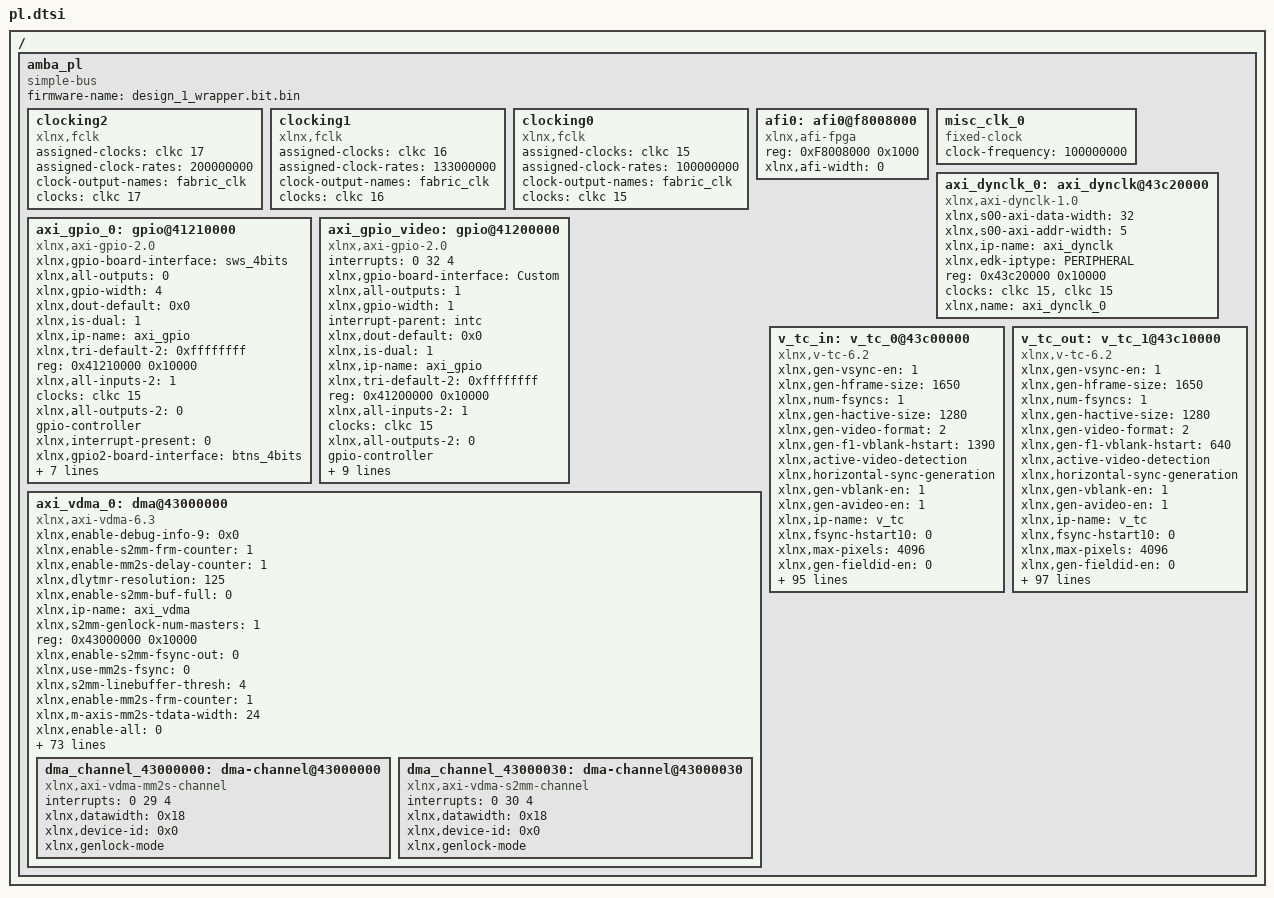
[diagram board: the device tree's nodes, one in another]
/ {
	amba_pl: amba_pl {
		ranges;
		compatible = "simple-bus";
		#address-cells = <1>;
		#size-cells = <1>;
		firmware-name = "design_1_wrapper.bit.bin";
		clocking2: clocking2 {
			compatible = "xlnx,fclk";
			assigned-clocks = <&clkc 17>;
			assigned-clock-rates = <200000000>;
			#clock-cells = <0>;
			clock-output-names = "fabric_clk";
			clocks = <&clkc 17>;
		};
		clocking1: clocking1 {
			compatible = "xlnx,fclk";
			assigned-clocks = <&clkc 16>;
			assigned-clock-rates = <133000000>;
			#clock-cells = <0>;
			clock-output-names = "fabric_clk";
			clocks = <&clkc 16>;
		};
		clocking0: clocking0 {
			compatible = "xlnx,fclk";
			assigned-clocks = <&clkc 15>;
			assigned-clock-rates = <100000000>;
			#clock-cells = <0>;
			clock-output-names = "fabric_clk";
			clocks = <&clkc 15>;
		};
		afi0: afi0@f8008000 {
			status = "okay";
			compatible = "xlnx,afi-fpga";
			#address-cells = <1>;
			reg = <0xF8008000 0x1000>;
			#size-cells = <0>;
			xlnx,afi-width = <0>;
		};
		misc_clk_0: misc_clk_0 {
			compatible = "fixed-clock";
			clock-frequency = <100000000>;
			#clock-cells = <0>;
		};
		axi_dynclk_0: axi_dynclk@43c20000 {
			xlnx,s00-axi-data-width = <32>;
			compatible = "xlnx,axi-dynclk-1.0";
			status = "okay";
			clock-names = "REF_CLK_I" , "s00_axi_aclk";
			xlnx,s00-axi-addr-width = <5>;
			xlnx,ip-name = "axi_dynclk";
			xlnx,edk-iptype = "PERIPHERAL";
			reg = <0x43c20000 0x10000>;
			clocks = <&clkc 15>, <&clkc 15>;
			xlnx,name = "axi_dynclk_0";
		};
		axi_gpio_0: gpio@41210000 {
			xlnx,gpio-board-interface = "sws_4bits";
			compatible = "xlnx,axi-gpio-2.0" , "xlnx,xps-gpio-1.00.a";
			xlnx,all-outputs = <0>;
			#gpio-cells = <2>;
			xlnx,gpio-width = <4>;
			xlnx,dout-default = <0x0>;
			xlnx,is-dual = <1>;
			xlnx,ip-name = "axi_gpio";
			xlnx,tri-default-2 = <0xffffffff>;
			reg = <0x41210000 0x10000>;
			xlnx,all-inputs-2 = <1>;
			clocks = <&clkc 15>;
			xlnx,all-outputs-2 = <0>;
			gpio-controller;
			xlnx,interrupt-present = <0>;
			xlnx,gpio2-board-interface = "btns_4bits";
			xlnx,edk-iptype = "PERIPHERAL";
			xlnx,dout-default-2 = <0x0>;
			status = "okay";
			xlnx,gpio2-width = <4>;
			clock-names = "s_axi_aclk";
			xlnx,use-board-flow;
			xlnx,tri-default = <0xffffffff>;
			xlnx,name = "axi_gpio_0";
			xlnx,all-inputs = <1>;
		};
		axi_gpio_video: gpio@41200000 {
			#interrupt-cells = <2>;
			interrupts = < 0 32 4 >;
			xlnx,gpio-board-interface = "Custom";
			compatible = "xlnx,axi-gpio-2.0" , "xlnx,xps-gpio-1.00.a";
			xlnx,all-outputs = <1>;
			#gpio-cells = <2>;
			xlnx,gpio-width = <1>;
			interrupt-parent = <&intc>;
			xlnx,dout-default = <0x0>;
			xlnx,is-dual = <1>;
			xlnx,ip-name = "axi_gpio";
			xlnx,tri-default-2 = <0xffffffff>;
			reg = <0x41200000 0x10000>;
			xlnx,all-inputs-2 = <1>;
			clocks = <&clkc 15>;
			xlnx,all-outputs-2 = <0>;
			gpio-controller;
			xlnx,interrupt-present = <1>;
			xlnx,gpio2-board-interface = "Custom";
			xlnx,edk-iptype = "PERIPHERAL";
			xlnx,dout-default-2 = <0x0>;
			status = "okay";
			xlnx,gpio2-width = <1>;
			clock-names = "s_axi_aclk";
			interrupt-controller;
			interrupt-names = "ip2intc_irpt";
			xlnx,tri-default = <0xffffffff>;
			xlnx,name = "axi_gpio_video";
			xlnx,all-inputs = <0>;
		};
		axi_vdma_0: dma@43000000 {
			xlnx,enable-debug-info-9 = <0x0>;
			xlnx,enable-s2mm-frm-counter = <1>;
			xlnx,enable-mm2s-delay-counter = <1>;
			xlnx,dlytmr-resolution = <125>;
			xlnx,enable-s2mm-buf-full = <0>;
			xlnx,ip-name = "axi_vdma";
			xlnx,s2mm-genlock-num-masters = <1>;
			reg = <0x43000000 0x10000>;
			xlnx,enable-s2mm-fsync-out = <0>;
			xlnx,use-mm2s-fsync = <0>;
			xlnx,s2mm-linebuffer-thresh = <4>;
			xlnx,enable-mm2s-frm-counter = <1>;
			xlnx,m-axis-mm2s-tdata-width = <24>;
			xlnx,enable-all = <0>;
			xlnx,dynamic-resolution = <1>;
			xlnx,enable-s2mm-rst-out = <0>;
			interrupt-names = "mm2s_introut" , "s2mm_introut";
			xlnx,s2mm-sof-enable = <0x1>;
			xlnx,mm2s-genlock-num-masters = <1>;
			xlnx,enable-mm2s-fsync-out = <0>;
			xlnx,mm2s-linebuffer-thresh = <4>;
			compatible = "xlnx,axi-vdma-6.3" , "xlnx,axi-vdma-1.00.a";
			xlnx,enable-tstvec = <0>;
			interrupt-parent = <&intc>;
			xlnx,s2mm-max-burst-length = <32>;
			xlnx,enable-mm2s-rst-out = <0>;
			xlnx,mm2s-sof-enable = <1>;
			xlnx,include-s2mm-dre = <0x0>;
			xlnx,enable-s2mm-frmstr-reg = <0>;
			xlnx,m-axi-s2mm-data-width = <64>;
			xlnx,enable-s2mm-sts-reg = <0>;
			xlnx,mm2s-max-burst-length = <8>;
			status = "okay";
			xlnx,include-mm2s-dre = <0x0>;
			xlnx,name = "axi_vdma_0";
			xlnx,enable-mm2s-frmstr-reg = <0>;
			interrupts = < 0 29 4 0 30 4 >;
			xlnx,m-axi-mm2s-data-width = <64>;
			xlnx,flush-on-fsync = <0x1>;
			xlnx,include-s2mm-sf = <1>;
			xlnx,single-interface = <0>;
			xlnx,s2mm-linebuffer-depth = <0x800>;
			xlnx,include-s2mm = <0x1>;
			xlnx,addr-width = <32>;
			clocks = <&clkc 16>, <&clkc 16>, <&clkc 16>, <&clkc 15>, <&clkc 16>;
			xlnx,s-axis-s2mm-tdata-width = <24>;
			xlnx,enable-debug-info-10 = <0>;
			xlnx,addrwidth = <0x20>;
			xlnx,enable-debug-info-11 = <0>;
			xlnx,edk-iptype = "PERIPHERAL";
			xlnx,enable-debug-info-12 = <0>;
			xlnx,use-fsync = <1>;
			xlnx,s2mm-genlock-repeat-en = <1>;
			xlnx,enable-debug-info-13 = <0x0>;
			xlnx,enable-vert-flip = <0x0>;
			xlnx,include-mm2s-sf = <0>;
			xlnx,enable-debug-info-14 = <0x1>;
			xlnx,include-internal-genlock = <0x1>;
			clock-names = "m_axi_mm2s_aclk" , "m_axi_s2mm_aclk" , "m_axis_mm2s_aclk" , "s_axi_lite_aclk" , "s_axis_s2mm_aclk";
			xlnx,enable-debug-info-15 = <0x1>;
			xlnx,mm2s-linebuffer-depth = <0x800>;
			xlnx,include-mm2s = <0x1>;
			xlnx,s2mm-genlock-mode = <0x2>;
			xlnx,flush-fsync = <0x1>;
			xlnx,select-xpm = <0>;
			xlnx,s2mm-data-width = <0x40>;
			xlnx,num-fstores = <0x3>;
			xlnx,enable-s2mm-param-updt = <0>;
			xlnx,enable-vidparam-reads = <0x1>;
			xlnx,mm2s-genlock-repeat-en = <0>;
			xlnx,prmry-is-aclk-async = <0>;
			xlnx,s2mm-tdata-width = <0x18>;
			#dma-cells = <1>;
			xlnx,enable-vidprmtr-reads = <1>;
			xlnx,mm2s-genlock-mode = <0x3>;
			xlnx,enable-debug-info-0 = <0>;
			xlnx,enable-debug-all = <0x0>;
			xlnx,enable-debug-info-1 = <0x0>;
			xlnx,mm2s-data-width = <0x40>;
			xlnx,enable-debug-info-2 = <0>;
			xlnx,enable-mm2s-param-updt = <0>;
			xlnx,enable-debug-info-3 = <0>;
			xlnx,enable-s2mm-delay-counter = <1>;
			xlnx,enable-debug-info-4 = <0>;
			xlnx,enable-debug-info-5 = <0x0>;
			xlnx,mm2s-tdata-width = <0x18>;
			xlnx,enable-debug-info-6 = <0x1>;
			xlnx,enable-debug-info-7 = <0x1>;
			xlnx,use-s2mm-fsync = <2>;
			xlnx,enable-debug-info-8 = <0>;
			xlnx,enable-mm2s-buf-empty = <0>;
			dma_channel_43000000: dma-channel@43000000 {
				interrupts = < 0 29 4 >;
				xlnx,datawidth = <0x18>;
				xlnx,device-id = <0x0>;
				compatible = "xlnx,axi-vdma-mm2s-channel";
				xlnx,genlock-mode;
			};
			dma_channel_43000030: dma-channel@43000030 {
				interrupts = < 0 30 4 >;
				xlnx,datawidth = <0x18>;
				xlnx,device-id = <0x0>;
				compatible = "xlnx,axi-vdma-s2mm-channel";
				xlnx,genlock-mode;
			};
		};
		v_tc_in: v_tc_0@43c00000 {
			xlnx,gen-vsync-en = <1>;
			xlnx,gen-hframe-size = <1650>;
			xlnx,num-fsyncs = <1>;
			xlnx,gen-hactive-size = <1280>;
			xlnx,gen-video-format = <2>;
			xlnx,gen-f1-vblank-hstart = <1390>;
			xlnx,active-video-detection;
			xlnx,horizontal-sync-generation;
			xlnx,gen-vblank-en = <1>;
			xlnx,gen-avideo-en = <1>;
			xlnx,ip-name = "v_tc";
			xlnx,fsync-hstart10 = <0>;
			xlnx,max-pixels = <4096>;
			xlnx,gen-fieldid-en = <0>;
			reg = <0x43c00000 0x10000>;
			xlnx,det-vblank-en = <0>;
			xlnx,fsync-hstart11 = <0>;
			xlnx,fsync-hstart12 = <0>;
			xlnx,pixels-per-clock = <0x4>;
			xlnx,gen-interlaced = <0>;
			xlnx,det-avideo-en = <1>;
			xlnx,fsync-hstart13 = <0>;
			xlnx,fsync-hstart14 = <0>;
			xlnx,gen-f0-vblank-hend = <640>;
			xlnx,fsync-hstart15 = <0>;
			xlnx,det-hsync-en = <1>;
			interrupt-names = "irq";
			xlnx,gen-avideo-polarity = <1>;
			xlnx,max-lines-per-frame = <4096>;
			xlnx,has-axi4-lite = <1>;
			compatible = "xlnx,v-tc-6.2" , "xlnx,bridge-v-tc-6.1";
			xlnx,max-clocks-per-line = <4096>;
			xlnx,gen-f0-vframe-size = <750>;
			xlnx,gen-f0-vblank-hstart = <640>;
			interrupt-parent = <&intc>;
			xlnx,max-lines = <4096>;
			xlnx,gen-f0-vsync-vstart = <724>;
			xlnx,horizontal-blank-generation;
			xlnx,gen-hsync-end = <1430>;
			xlnx,gen-f0-vsync-hstart = <640>;
			xlnx,gen-f1-vsync-hend = <1390>;
			xlnx,gen-vsync-polarity = <1>;
			xlnx,fsync-vstart0 = <0>;
			xlnx,gen-hsync-polarity = <1>;
			xlnx,fsync-vstart1 = <0>;
			status = "okay";
			xlnx,fsync-vstart2 = <0>;
			xlnx,gen-hsync-start = <1390>;
			xlnx,gen-f0-vsync-vend = <729>;
			xlnx,fsync-vstart3 = <0>;
			xlnx,vertical-sync-detection;
			xlnx,frame-syncs = <1>;
			xlnx,fsync-vstart4 = <0>;
			xlnx,gen-vactive-size = <720>;
			xlnx,name = "v_tc_in";
			xlnx,fsync-vstart5 = <0>;
			xlnx,detector;
			interrupts = < 0 31 4 >;
			xlnx,gen-achroma-en = <0>;
			xlnx,fsync-vstart6 = <0>;
			xlnx,det-fieldid-en = <0>;
			xlnx,fsync-vstart7 = <0>;
			xlnx,gen-hsync-en = <1>;
			xlnx,fsync-vstart8 = <0>;
			xlnx,fsync-vstart10 = <0>;
			xlnx,fsync-vstart9 = <0>;
			xlnx,fsync-vstart11 = <0>;
			xlnx,arbitrary-res-en = /bits/ 8 <0x0>;
			xlnx,fsync-vstart12 = <0>;
			xlnx,fsync-vstart13 = <0>;
			clocks = <&misc_clk_0>, <&clkc 15>;
			xlnx,fsync-vstart14 = <0>;
			xlnx,fsync-vstart15 = <0>;
			xlnx,enable-detection;
			xlnx,gen-cparity = <0>;
			xlnx,edk-iptype = "PERIPHERAL";
			xlnx,vertical-sync-generation;
			xlnx,gen-f1-vblank-hend = <1390>;
			xlnx,det-vsync-en = <1>;
			xlnx,gen-vblank-polarity = <1>;
			xlnx,fsync-hstart0 = <0>;
			clock-names = "clk" , "s_axi_aclk";
			xlnx,interlace-en = <0>;
			xlnx,gen-auto-switch = <0>;
			xlnx,fsync-hstart1 = <0>;
			xlnx,fsync-hstart2 = <0>;
			xlnx,active-video-generation;
			xlnx,fsync-hstart3 = <0>;
			xlnx,fsync-hstart4 = <0>;
			xlnx,fsync-hstart5 = <0>;
			xlnx,gen-f1-vframe-size = <750>;
			xlnx,fsync-hstart6 = <0>;
			xlnx,fsync-hstart7 = <0>;
			xlnx,fsync-hstart8 = <0>;
			xlnx,gen-hblank-en = <1>;
			xlnx,fsync-hstart9 = <0>;
			xlnx,horizontal-sync-detection;
			xlnx,gen-f1-vsync-vend = <729>;
			xlnx,detect-en = <1>;
			xlnx,det-hblank-en = <0>;
			xlnx,vid-ppc = <4>;
			xlnx,has-intc-if = <1>;
			xlnx,generate-en = <0>;
			xlnx,gen-achroma-polarity = <1>;
			xlnx,sync-en = <0>;
			xlnx,det-achroma-en = <0>;
			xlnx,gen-f1-vsync-vstart = <724>;
			xlnx,vertical-blank-generation;
			xlnx,gen-hblank-polarity = <1>;
			xlnx,video-mode = "720p";
			xlnx,gen-fieldid-polarity = <1>;
			xlnx,gen-f1-vsync-hstart = <1390>;
			xlnx,gen-f0-vsync-hend = <695>;
		};
		v_tc_out: v_tc_1@43c10000 {
			xlnx,gen-vsync-en = <1>;
			xlnx,gen-hframe-size = <1650>;
			xlnx,num-fsyncs = <1>;
			xlnx,gen-hactive-size = <1280>;
			xlnx,gen-video-format = <2>;
			xlnx,gen-f1-vblank-hstart = <640>;
			xlnx,active-video-detection;
			xlnx,horizontal-sync-generation;
			xlnx,gen-vblank-en = <1>;
			xlnx,gen-avideo-en = <1>;
			xlnx,ip-name = "v_tc";
			xlnx,fsync-hstart10 = <0>;
			xlnx,max-pixels = <4096>;
			xlnx,gen-fieldid-en = <0>;
			reg = <0x43c10000 0x10000>;
			xlnx,det-vblank-en = <1>;
			xlnx,fsync-hstart11 = <0>;
			xlnx,fsync-hstart12 = <0>;
			xlnx,pixels-per-clock = <0x4>;
			xlnx,gen-interlaced = <0>;
			xlnx,det-avideo-en = <1>;
			xlnx,fsync-hstart13 = <0>;
			xlnx,fsync-hstart14 = <0>;
			xlnx,gen-f0-vblank-hend = <640>;
			xlnx,fsync-hstart15 = <0>;
			xlnx,det-hsync-en = <1>;
			interrupt-names = "irq";
			xlnx,enable-generation;
			xlnx,gen-avideo-polarity = <1>;
			xlnx,max-lines-per-frame = <4096>;
			xlnx,has-axi4-lite = <1>;
			compatible = "xlnx,v-tc-6.2" , "xlnx,bridge-v-tc-6.1";
			xlnx,max-clocks-per-line = <4096>;
			xlnx,gen-f0-vframe-size = <750>;
			xlnx,gen-f0-vblank-hstart = <640>;
			interrupt-parent = <&intc>;
			xlnx,max-lines = <4096>;
			xlnx,gen-f0-vsync-vstart = <724>;
			xlnx,horizontal-blank-generation;
			xlnx,gen-hsync-end = <1430>;
			xlnx,gen-f0-vsync-hstart = <640>;
			xlnx,gen-f1-vsync-hend = <695>;
			xlnx,vertical-blank-detection;
			xlnx,gen-vsync-polarity = <1>;
			xlnx,fsync-vstart0 = <0>;
			xlnx,gen-hsync-polarity = <1>;
			xlnx,fsync-vstart1 = <0>;
			status = "okay";
			xlnx,fsync-vstart2 = <0>;
			xlnx,gen-hsync-start = <1390>;
			xlnx,gen-f0-vsync-vend = <729>;
			xlnx,fsync-vstart3 = <0>;
			xlnx,vertical-sync-detection;
			xlnx,frame-syncs = <1>;
			xlnx,fsync-vstart4 = <0>;
			xlnx,gen-vactive-size = <720>;
			xlnx,name = "v_tc_out";
			xlnx,fsync-vstart5 = <0>;
			interrupts = < 0 33 4 >;
			xlnx,gen-achroma-en = <0>;
			xlnx,fsync-vstart6 = <0>;
			xlnx,det-fieldid-en = <0>;
			xlnx,fsync-vstart7 = <0>;
			xlnx,gen-hsync-en = <1>;
			xlnx,fsync-vstart8 = <0>;
			xlnx,fsync-vstart10 = <0>;
			xlnx,fsync-vstart9 = <0>;
			xlnx,fsync-vstart11 = <0>;
			xlnx,arbitrary-res-en = /bits/ 8 <0x0>;
			xlnx,fsync-vstart12 = <0>;
			xlnx,fsync-vstart13 = <0>;
			clocks = <&misc_clk_0>, <&clkc 15>;
			xlnx,fsync-vstart14 = <0>;
			xlnx,fsync-vstart15 = <0>;
			xlnx,gen-cparity = <0>;
			xlnx,edk-iptype = "PERIPHERAL";
			xlnx,vertical-sync-generation;
			xlnx,gen-f1-vblank-hend = <640>;
			xlnx,det-vsync-en = <1>;
			xlnx,gen-vblank-polarity = <1>;
			xlnx,fsync-hstart0 = <0>;
			clock-names = "clk" , "s_axi_aclk";
			xlnx,interlace-en = <0>;
			xlnx,gen-auto-switch = <0>;
			xlnx,fsync-hstart1 = <0>;
			xlnx,fsync-hstart2 = <0>;
			xlnx,active-video-generation;
			xlnx,fsync-hstart3 = <0>;
			xlnx,fsync-hstart4 = <0>;
			xlnx,horizontal-blank-detection;
			xlnx,fsync-hstart5 = <0>;
			xlnx,gen-f1-vframe-size = <750>;
			xlnx,fsync-hstart6 = <0>;
			xlnx,fsync-hstart7 = <0>;
			xlnx,fsync-hstart8 = <0>;
			xlnx,gen-hblank-en = <1>;
			xlnx,fsync-hstart9 = <0>;
			xlnx,horizontal-sync-detection;
			xlnx,gen-f1-vsync-vend = <729>;
			xlnx,detect-en = <0>;
			xlnx,det-hblank-en = <1>;
			xlnx,vid-ppc = <4>;
			xlnx,has-intc-if = <0>;
			xlnx,generate-en = <1>;
			xlnx,gen-achroma-polarity = <1>;
			xlnx,sync-en = <0>;
			xlnx,det-achroma-en = <0>;
			xlnx,generator;
			xlnx,gen-f1-vsync-vstart = <724>;
			xlnx,vertical-blank-generation;
			xlnx,gen-hblank-polarity = <1>;
			xlnx,video-mode = "720p";
			xlnx,gen-fieldid-polarity = <1>;
			xlnx,gen-f1-vsync-hstart = <695>;
			xlnx,gen-f0-vsync-hend = <695>;
		};
	};
};
